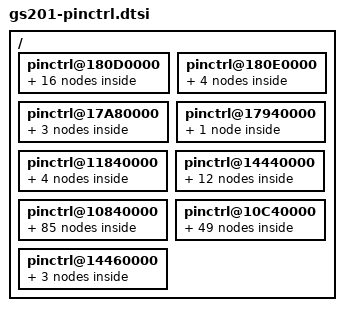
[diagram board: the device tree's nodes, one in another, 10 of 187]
// SPDX-License-Identifier: GPL-2.0-only
/*
 * Copyright 2021 Google LLC.
 *
 */

#include <dt-bindings/interrupt-controller/gs201.h>
#include <arm64/exynos/exynos-pinctrl.h>
#include "gs101-pinctrl.h"

/ {
	/* GPIO_ALIVE */
	pinctrl@180D0000 {
		gpa0: gpa0 {
			gpio-controller;
			#gpio-cells = <2>;
			interrupt-controller;
			#interrupt-cells = <3>;
			interrupt-parent = <&gic>;
			interrupts = <GIC_SPI IRQ_ALIVE_EINT0 ITLH>,
				   <GIC_SPI IRQ_ALIVE_EINT1 ITLH>,
				   <GIC_SPI IRQ_ALIVE_EINT2 ITLH>,
				   <GIC_SPI IRQ_ALIVE_EINT3 ITLH>,
				   <GIC_SPI IRQ_ALIVE_EINT4 ITLH>,
				   <GIC_SPI IRQ_ALIVE_EINT5 ITLH>,
				   <GIC_SPI IRQ_ALIVE_EINT6 ITLH>,
				   <GIC_SPI IRQ_ALIVE_EINT7 ITLH>;
		};
		gpa1: gpa1 {
			gpio-controller;
			#gpio-cells = <2>;
			interrupt-controller;
			#interrupt-cells = <3>;
			interrupt-parent = <&gic>;
			interrupts = <GIC_SPI IRQ_ALIVE_EINT8 ITLH>,
				   <GIC_SPI IRQ_ALIVE_EINT9 ITLH>,
				   <GIC_SPI IRQ_ALIVE_EINT10 ITLH>,
				   <GIC_SPI IRQ_ALIVE_EINT11 ITLH>,
				   <GIC_SPI IRQ_ALIVE_EINT12 ITLH>,
				   <GIC_SPI IRQ_ALIVE_EINT13 ITLH>,
				   <GIC_SPI IRQ_ALIVE_EINT14 ITLH>;
		};
		gpa2: gpa2 {
			gpio-controller;
			#gpio-cells = <2>;
			interrupt-controller;
			#interrupt-cells = <3>;
			interrupt-parent = <&gic>;
			interrupts = <GIC_SPI IRQ_ALIVE_EINT15 ITLH>,
				   <GIC_SPI IRQ_ALIVE_EINT16 ITLH>,
				   <GIC_SPI IRQ_ALIVE_EINT17 ITLH>,
				   <GIC_SPI IRQ_ALIVE_EINT18 ITLH>;
		};
		gpa3: gpa3 {
			gpio-controller;
			#gpio-cells = <2>;
			interrupt-controller;
			#interrupt-cells = <3>;
			interrupt-parent = <&gic>;
			interrupts = <GIC_SPI IRQ_ALIVE_EINT20 ITLH>,
				   <GIC_SPI IRQ_ALIVE_EINT21 ITLH>,
				   <GIC_SPI IRQ_ALIVE_EINT22 ITLH>,
				   <GIC_SPI IRQ_ALIVE_EINT23 ITLH>;
		};
		gpa4: gpa4 {
			gpio-controller;
			#gpio-cells = <2>;
			interrupt-controller;
			#interrupt-cells = <3>;
			interrupt-parent = <&gic>;
			interrupts = <GIC_SPI IRQ_ALIVE_EINT24 ITLH>,
				   <GIC_SPI IRQ_ALIVE_EINT25 ITLH>,
				   <GIC_SPI IRQ_ALIVE_EINT26 ITLH>,
				   <GIC_SPI IRQ_ALIVE_EINT27 ITLH>;
		};
		gpa5: gpa5 {
			gpio-controller;
			#gpio-cells = <2>;
			interrupt-controller;
			#interrupt-cells = <3>;
			interrupts = <GIC_SPI IRQ_ALIVE_EINT28 ITLH>,
				   <GIC_SPI IRQ_ALIVE_EINT29 ITLH>,
				   <GIC_SPI IRQ_ALIVE_EINT30 ITLH>,
				   <GIC_SPI IRQ_ALIVE_EINT31 ITLH>,
				   <GIC_SPI IRQ_ALIVE_EINT32 ITLH>,
				   <GIC_SPI IRQ_ALIVE_EINT33 ITLH>,
				   <GIC_SPI IRQ_ALIVE_EINT34 ITLH>;
		};
		gpa9: gpa9 {
			gpio-controller;
			#gpio-cells = <2>;
			interrupt-controller;
			#interrupt-cells = <3>;
			interrupts = <GIC_SPI IRQ_ALIVE_EINT35 ITLH>,
				   <GIC_SPI IRQ_ALIVE_EINT36 ITLH>,
				   <GIC_SPI IRQ_ALIVE_EINT37 ITLH>,
				   <GIC_SPI IRQ_ALIVE_EINT38 ITLH>,
				   <GIC_SPI IRQ_ALIVE_EINT39 ITLH>,
				   <GIC_SPI IRQ_ALIVE_EINT40 ITLH>,
				   <GIC_SPI IRQ_ALIVE_EINT41 ITLH>,
				   <GIC_SPI IRQ_ALIVE_EINT42 ITLH>;
		};
		gpa10: gpa10 {
			gpio-controller;
			#gpio-cells = <2>;
			interrupt-controller;
			#interrupt-cells = <3>;
			interrupts = <GIC_SPI IRQ_ALIVE_EINT43 ITLH>,
				   <GIC_SPI IRQ_ALIVE_EINT44 ITLH>;
		};

		uart17_bus: uart17-bus {
		       samsung,pins = "gpa2-2", "gpa2-3";
		       samsung,pin-function = <2>;
		       samsung,pin-pud = <0>;
		};

		uart18_bus: uart18-bus {
		       samsung,pins = "gpa3-0", "gpa3-1", "gpa3-2", "gpa3-3";
		       samsung,pin-function = <EXYNOS_PIN_FUNC_2>;
		       samsung,pin-pud = <EXYNOS_PIN_PULL_NONE>;
		};

		uart18_bus_rts: uart1-bus-rts {
		       samsung,pins = "gpa3-2";
		       samsung,pin-function = <EXYNOS_PIN_FUNC_OUTPUT>;
		       samsung,pin-pud = <EXYNOS_PIN_PULL_NONE>;
		       samsung,pin-val = <1>;
		};

		uart18_bus_tx_dat: uart1-bus-tx-dat {
		       samsung,pins = "gpa3-1";
		       samsung,pin-val = <1>;
		};

		uart18_bus_tx_con: uart1-bus-tx-con {
		       samsung,pins = "gpa3-1";
		       samsung,pin-function = <EXYNOS_PIN_FUNC_OUTPUT>;
		};

		uart19_bus: uart19-bus {
		       samsung,pins = "gpa4-0", "gpa4-1", "gpa4-2", "gpa4-3";
		       samsung,pin-function = <2>;
		       samsung,pin-pud = <0>;
		};

		spi17_bus: spi17-bus {
			samsung,pins = "gpa4-0", "gpa4-1", "gpa4-2";
			samsung,pin-function = <EXYNOS_PIN_FUNC_2>;
			samsung,pin-pud = <EXYNOS_PIN_PULL_NONE>;
			samsung,pin-drv = <GS101_PIN_DRV_2_5_MA>;
		};

		spi17_cs: spi17-cs {
			samsung,pins = "gpa4-3";
			samsung,pin-function = <EXYNOS_PIN_FUNC_OUTPUT>;
			samsung,pin-pud = <EXYNOS_PIN_PULL_NONE>;
			samsung,pin-drv = <GS101_PIN_DRV_2_5_MA>;
		};
	};
	/* GPIO_FAR_ALIVE */
	pinctrl@180E0000 {
		gpa6: gpa6 {
			gpio-controller;
			#gpio-cells = <2>;
			interrupt-controller;
			#interrupt-cells = <3>;
			interrupt-parent = <&gic>;
			interrupts = <GIC_SPI IRQ_ALIVE_EINT45 ITLH>,
				   <GIC_SPI IRQ_ALIVE_EINT46 ITLH>,
				   <GIC_SPI IRQ_ALIVE_EINT47 ITLH>,
				   <GIC_SPI IRQ_ALIVE_EINT48 ITLH>,
				   <GIC_SPI IRQ_ALIVE_EINT49 ITLH>,
				   <GIC_SPI IRQ_ALIVE_EINT50 ITLH>,
				   <GIC_SPI IRQ_ALIVE_EINT51 ITLH>,
				   <GIC_SPI IRQ_ALIVE_EINT52 ITLH>;
		};
		gpa7: gpa7 {
			gpio-controller;
			#gpio-cells = <2>;
			interrupt-controller;
			#interrupt-cells = <3>;
			interrupt-parent = <&gic>;
			interrupts = <GIC_SPI IRQ_ALIVE_EINT53 ITLH>,
				   <GIC_SPI IRQ_ALIVE_EINT54 ITLH>,
				   <GIC_SPI IRQ_ALIVE_EINT55 ITLH>,
				   <GIC_SPI IRQ_ALIVE_EINT56 ITLH>;
		};
		gpa8: gpa8 {
			gpio-controller;
			#gpio-cells = <2>;
			interrupt-controller;
			#interrupt-cells = <3>;
			interrupt-parent = <&gic>;
			interrupts = <GIC_SPI IRQ_ALIVE_EINT57 ITLH>,
				   <GIC_SPI IRQ_ALIVE_EINT58 ITLH>,
				   <GIC_SPI IRQ_ALIVE_EINT59 ITLH>,
				   <GIC_SPI IRQ_ALIVE_EINT60 ITLH>,
				   <GIC_SPI IRQ_ALIVE_EINT61 ITLH>,
				   <GIC_SPI IRQ_ALIVE_EINT62 ITLH>,
				   <GIC_SPI IRQ_ALIVE_EINT63 ITLH>,
				   <GIC_SPI IRQ_ALIVE_EINT64 ITLH>;
		};
		gpa11: gpa11 {
			gpio-controller;
			#gpio-cells = <2>;
			interrupt-controller;
			#interrupt-cells = <3>;
			interrupt-parent = <&gic>;
			interrupts = <GIC_SPI IRQ_ALIVE_EINT65 ITLH>,
				   <GIC_SPI IRQ_ALIVE_EINT66 ITLH>;
		};

	};
	/* GPIO_GSACORE */
	pinctrl@17A80000 {
		gps0: gps0 {
			gpio-controller;
			#gpio-cells = <2>;
			interrupt-controller;
			#interrupt-cells = <3>;
		};
		gps1: gps1 {
			gpio-controller;
			#gpio-cells = <2>;
			interrupt-controller;
			#interrupt-cells = <3>;
		};
		gps2: gps2 {
			gpio-controller;
			#gpio-cells = <2>;
			interrupt-controller;
			#interrupt-cells = <3>;
		};
	};
	/* GPIO_GSACTRL */
	pinctrl@17940000 {
		gps3: gps3 {
			gpio-controller;
			#gpio-cells = <2>;
			interrupt-controller;
			#interrupt-cells = <3>;
		};
	};
	/* GPIO_HSI1 */
	pinctrl@11840000 {
		gph0: gph0 {
			gpio-controller;
			#gpio-cells = <2>;
			interrupt-controller;
			#interrupt-cells = <3>;
		};
		gph1: gph1 {
			gpio-controller;
			#gpio-cells = <2>;
			interrupt-controller;
			#interrupt-cells = <3>;
		};
		pcie0_clkreq: pcie0_clkreq {
			samsung,pins = "gph0-1";
			samsung,pin-function = <2>;
			samsung,pin-pud = <3>;
			samsung,pin-drv = <GS101_PIN_DRV_2_5_MA>;
			samsung,pin-con-pdn = <3>;
			samsung,pin-pud-pdn = <3>;
		};
		pcie0_perst: pcie0_perst {
			samsung,pins = "gph0-0";
			samsung,pin-function = <1>;
			samsung,pin-drv = <GS101_PIN_DRV_2_5_MA>;
			samsung,pin-con-pdn = <3>;
		};
	};
	/* GPIO_HSI2 */
	pinctrl@14440000 {
		gph2: gph2 {
			gpio-controller;
			#gpio-cells = <2>;
			interrupt-controller;
			#interrupt-cells = <3>;
		};
		gph4: gph4 {
			gpio-controller;
			#gpio-cells = <2>;
			interrupt-controller;
			#interrupt-cells = <3>;
		};

		sd2_clk: sd2-clk {
			samsung,pins = "gph4-0";
			samsung,pin-function = <2>;
			samsung,pin-pud = <0>;
			samsung,pin-drv = <GS101_PIN_DRV_7_5_MA>;
		};

		sd2_cmd: sd2-cmd {
			samsung,pins = "gph4-1";
			samsung,pin-function = <2>;
			samsung,pin-pud = <3>;
			samsung,pin-drv = <GS101_PIN_DRV_7_5_MA>;
		};

		sd2_bus1: sd2-bus-width1 {
			samsung,pins = "gph4-2";
			samsung,pin-function = <2>;
			samsung,pin-pud = <3>;
			samsung,pin-drv = <GS101_PIN_DRV_7_5_MA>;
		};

		sd2_bus4: sd2-bus-width4 {
			samsung,pins = "gph4-3", "gph4-4", "gph4-5";
			samsung,pin-function = <2>;
			samsung,pin-pud = <3>;
			samsung,pin-drv = <GS101_PIN_DRV_7_5_MA>;
		};

		sd2_clk_fast_slew_rate_1x: sd2-clk_fast_slew_rate_1x {
			samsung,pins = "gph4-0";
			samsung,pin-function = <2>;
			samsung,pin-pud = <0>;
			samsung,pin-drv = <GS101_PIN_DRV_2_5_MA>;
		};

		sd2_clk_fast_slew_rate_2x: sd2-clk_fast_slew_rate_2x {
			samsung,pins = "gph4-0";
			samsung,pin-function = <2>;
			samsung,pin-pud = <0>;
			samsung,pin-drv = <GS101_PIN_DRV_5_MA>;
		};

		sd2_clk_fast_slew_rate_3x: sd2-clk_fast_slew_rate_3x {
			samsung,pins = "gph4-0";
			samsung,pin-function = <2>;
			samsung,pin-pud = <0>;
			samsung,pin-drv = <GS101_PIN_DRV_7_5_MA>;
		};

		sd2_clk_fast_slew_rate_4x: sd2-clk_fast_slew_rate_4x {
			samsung,pins = "gph4-0";
			samsung,pin-function = <2>;
			samsung,pin-pud = <0>;
			samsung,pin-drv = <GS101_PIN_DRV_10_MA>;
		};
		pcie1_clkreq: pcie1_clkreq {
			samsung,pins = "gph2-1";
			samsung,pin-function = <2>;
			samsung,pin-pud = <3>;
			samsung,pin-drv = <GS101_PIN_DRV_2_5_MA>;
			samsung,pin-con-pdn = <3>;
			samsung,pin-pud-pdn = <3>;
		};
		pcie1_perst: pcie1_perst {
			samsung,pins = "gph2-0";
			samsung,pin-function = <1>;
			samsung,pin-drv = <GS101_PIN_DRV_2_5_MA>;
			samsung,pin-pud = <EXYNOS_PIN_PULL_NONE>;
			samsung,pin-pud-pdn = <EXYNOS_PIN_PULL_NONE>;
			samsung,pin-con-pdn = <3>;
		};
	};
	/* GPIO_PERIC0 */
	pinctrl@10840000 {
		gpp0: gpp0 {
			gpio-controller;
			#gpio-cells = <2>;
			interrupt-controller;
			#interrupt-cells = <3>;
		};
		gpp1: gpp1 {
			gpio-controller;
			#gpio-cells = <2>;
			interrupt-controller;
			#interrupt-cells = <3>;
		};
		gpp2: gpp2 {
			gpio-controller;
			#gpio-cells = <2>;
			interrupt-controller;
			#interrupt-cells = <3>;
		};
		gpp3: gpp3 {
			gpio-controller;
			#gpio-cells = <2>;
			interrupt-controller;
			#interrupt-cells = <3>;
		};
		gpp4: gpp4 {
			gpio-controller;
			#gpio-cells = <2>;
			interrupt-controller;
			#interrupt-cells = <3>;
		};
		gpp5: gpp5 {
			gpio-controller;
			#gpio-cells = <2>;
			interrupt-controller;
			#interrupt-cells = <3>;
		};
		gpp6: gpp6 {
			gpio-controller;
			#gpio-cells = <2>;
			interrupt-controller;
			#interrupt-cells = <3>;
		};
		gpp7: gpp7 {
			gpio-controller;
			#gpio-cells = <2>;
			interrupt-controller;
			#interrupt-cells = <3>;
		};
		gpp8: gpp8 {
			gpio-controller;
			#gpio-cells = <2>;
			interrupt-controller;
			#interrupt-cells = <3>;
		};
		gpp9: gpp9 {
			gpio-controller;
			#gpio-cells = <2>;
			interrupt-controller;
			#interrupt-cells = <3>;
		};
		gpp10: gpp10 {
			gpio-controller;
			#gpio-cells = <2>;
			interrupt-controller;
			#interrupt-cells = <3>;
		};
		gpp11: gpp11 {
			gpio-controller;
			#gpio-cells = <2>;
			interrupt-controller;
			#interrupt-cells = <3>;
		};
		gpp12: gpp12 {
			gpio-controller;
			#gpio-cells = <2>;
			interrupt-controller;
			#interrupt-cells = <3>;
		};
		gpp13: gpp13 {
			gpio-controller;
			#gpio-cells = <2>;
			interrupt-controller;
			#interrupt-cells = <3>;
		};
		gpp14: gpp14 {
			gpio-controller;
			#gpio-cells = <2>;
			interrupt-controller;
			#interrupt-cells = <3>;
		};
		gpp15: gpp15 {
			gpio-controller;
			#gpio-cells = <2>;
			interrupt-controller;
			#interrupt-cells = <3>;
		};
		gpp16: gpp16 {
			gpio-controller;
			#gpio-cells = <2>;
			interrupt-controller;
			#interrupt-cells = <3>;
		};
		gpp17: gpp17 {
			gpio-controller;
			#gpio-cells = <2>;
			interrupt-controller;
			#interrupt-cells = <3>;
		};
		gpp18: gpp18 {
			gpio-controller;
			#gpio-cells = <2>;
			interrupt-controller;
			#interrupt-cells = <3>;
		};
		gpp19: gpp19 {
			gpio-controller;
			#gpio-cells = <2>;
			interrupt-controller;
			#interrupt-cells = <3>;
		};
		/* USI_PERIC0_UART_DBG */
		uart0_bus: uart0-bus {
			samsung,pins = "gpp1-2", "gpp1-3";
			samsung,pin-function = <2>;
			samsung,pin-pud = <0>;
		};

		disp_te_pri_on: disp-te-pri-on {
			samsung,pins = "gpp0-3";
			samsung,pin-function = <0xf>;
		};

		disp_te_pri_off: disp-te-pri-off {
			samsung,pins = "gpp0-3";
			samsung,pin-function = <0>;
		};

		disp_te_sec_on: disp-te-sec-on {
			samsung,pins = "gpp0-4";
			samsung,pin-function = <0xf>;
		};

		disp_te_sec_off: disp-te-sec-off {
			samsung,pins = "gpp0-4";
			samsung,pin-function = <0>;
		};

		sensor_mclk1_out: sensor-mclk1-out {
			samsung,pins = "gpp3-0";
			samsung,pin-function = <EXYNOS_PIN_FUNC_OUTPUT>;
			samsung,pin-pud = <EXYNOS_PIN_PULL_DOWN>;
			samsung,pin-drv = <GS101_PIN_DRV_2_5_MA>;
		};
		sensor_mclk1_fn: sensor-mclk1-fn {
			samsung,pins = "gpp3-0";
			samsung,pin-function = <EXYNOS_PIN_FUNC_2>;
			samsung,pin-pud = <EXYNOS_PIN_PULL_NONE>;
			samsung,pin-drv = <GS101_PIN_DRV_2_5_MA>;
		};
		sensor_mclk2_out: sensor-mclk2-out {
			samsung,pins = "gpp5-0";
			samsung,pin-function = <EXYNOS_PIN_FUNC_OUTPUT>;
			samsung,pin-pud = <EXYNOS_PIN_PULL_DOWN>;
			samsung,pin-drv = <GS101_PIN_DRV_2_5_MA>;
		};
		sensor_mclk2_fn: sensor-mclk2-fn {
			samsung,pins = "gpp5-0";
			samsung,pin-function = <EXYNOS_PIN_FUNC_2>;
			samsung,pin-pud = <EXYNOS_PIN_PULL_NONE>;
			samsung,pin-drv = <GS101_PIN_DRV_2_5_MA>;
		};
		sensor_mclk3_out: sensor-mclk3-out {
			samsung,pins = "gpp7-0";
			samsung,pin-function = <EXYNOS_PIN_FUNC_OUTPUT>;
			samsung,pin-pud = <EXYNOS_PIN_PULL_DOWN>;
			samsung,pin-drv = <GS101_PIN_DRV_2_5_MA>;
		};
		sensor_mclk3_fn: sensor-mclk3-fn {
			samsung,pins = "gpp7-0";
			samsung,pin-function = <EXYNOS_PIN_FUNC_2>;
			samsung,pin-pud = <EXYNOS_PIN_PULL_NONE>;
			samsung,pin-drv = <GS101_PIN_DRV_2_5_MA>;
		};
		sensor_mclk4_out: sensor-mclk4-out {
			samsung,pins = "gpp9-0";
			samsung,pin-function = <EXYNOS_PIN_FUNC_OUTPUT>;
			samsung,pin-pud = <EXYNOS_PIN_PULL_DOWN>;
			samsung,pin-drv = <GS101_PIN_DRV_2_5_MA>;
		};
		sensor_mclk4_fn: sensor-mclk4-fn {
			samsung,pins = "gpp9-0";
			samsung,pin-function = <EXYNOS_PIN_FUNC_2>;
			samsung,pin-pud = <EXYNOS_PIN_PULL_NONE>;
			samsung,pin-drv = <GS101_PIN_DRV_2_5_MA>;
		};
		sensor_mclk5_out: sensor-mclk5-out {
			samsung,pins = "gpp11-0";
			samsung,pin-function = <EXYNOS_PIN_FUNC_OUTPUT>;
			samsung,pin-pud = <EXYNOS_PIN_PULL_DOWN>;
			samsung,pin-drv = <GS101_PIN_DRV_5_MA>;
		};
		sensor_mclk5_fn: sensor-mclk5-fn {
			samsung,pins = "gpp11-0";
			samsung,pin-function = <EXYNOS_PIN_FUNC_2>;
			samsung,pin-pud = <EXYNOS_PIN_PULL_NONE>;
			samsung,pin-drv = <GS101_PIN_DRV_5_MA>;
		};
		sensor_mclk6_out: sensor-mclk6-out {
			samsung,pins = "gpp13-0";
			samsung,pin-function = <EXYNOS_PIN_FUNC_OUTPUT>;
			samsung,pin-pud = <EXYNOS_PIN_PULL_DOWN>;
			samsung,pin-drv = <GS101_PIN_DRV_5_MA>;
		};
		sensor_mclk6_fn: sensor-mclk6-fn {
			samsung,pins = "gpp13-0";
			samsung,pin-function = <EXYNOS_PIN_FUNC_2>;
			samsung,pin-pud = <EXYNOS_PIN_PULL_NONE>;
			samsung,pin-drv = <GS101_PIN_DRV_5_MA>;
		};
		sensor_mclk7_out: sensor-mclk7-out {
			samsung,pins = "gpp15-0";
			samsung,pin-function = <EXYNOS_PIN_FUNC_OUTPUT>;
			samsung,pin-pud = <EXYNOS_PIN_PULL_DOWN>;
			samsung,pin-drv = <GS101_PIN_DRV_5_MA>;
		};
		sensor_mclk7_fn: sensor-mclk7-fn {
			samsung,pins = "gpp15-0";
			samsung,pin-function = <EXYNOS_PIN_FUNC_2>;
			samsung,pin-pud = <EXYNOS_PIN_PULL_NONE>;
			samsung,pin-drv = <GS101_PIN_DRV_5_MA>;
		};
		sensor_mclk8_out: sensor-mclk8-out {
			samsung,pins = "gpp17-0";
			samsung,pin-function = <EXYNOS_PIN_FUNC_OUTPUT>;
			samsung,pin-pud = <EXYNOS_PIN_PULL_DOWN>;
			samsung,pin-drv = <GS101_PIN_DRV_5_MA>;
		};
		sensor_mclk8_fn: sensor-mclk8-fn {
			samsung,pins = "gpp17-0";
			samsung,pin-function = <EXYNOS_PIN_FUNC_2>;
			samsung,pin-pud = <EXYNOS_PIN_PULL_NONE>;
			samsung,pin-drv = <GS101_PIN_DRV_5_MA>;
		};
		hsi2c14_bus: hsi2c14-bus {
			samsung,pins = "gpp18-0", "gpp18-1";
			samsung,pin-function = <2>;
			samsung,pin-pud = <0>;
			samsung,pin-drv = <GS101_PIN_DRV_2_5_MA>;
		};
		uart14_bus_single: uart14-bus {
			samsung,pins = "gpp18-0", "gpp18-1",
			   "gpp18-2", "gpp18-3";
			samsung,pin-function = <2>;
			samsung,pin-pud = <0>;
		};
		spi14_bus: spi14-bus {
			samsung,pins = "gpp18-0", "gpp18-1", "gpp18-2";
			samsung,pin-function = <2>;
			samsung,pin-pud = <0>;
			samsung,pin-drv = <GS101_PIN_DRV_2_5_MA>;
		};
		spi14_cs: spi14-cs {
			samsung,pins = "gpp18-3";
			samsung,pin-function = <1>;
			samsung,pin-pud = <0>;
			samsung,pin-drv = <GS101_PIN_DRV_2_5_MA>;
		};
		spi14_cs_func: spi14-cs-func {
			samsung,pins = "gpp18-3";
			samsung,pin-function = <2>;
			samsung,pin-pud = <0>;
			samsung,pin-drv = <GS101_PIN_DRV_2_5_MA>;
		};
		hsi2c8_bus: hsi2c8-bus {
			samsung,pins = "gpp16-0", "gpp16-1";
			samsung,pin-function = <EXYNOS_PIN_FUNC_3>;
			samsung,pin-pud = <EXYNOS_PIN_PULL_NONE>;
			samsung,pin-drv = <GS101_PIN_DRV_2_5_MA>;
			samsung,pin-pud-pdn = <EXYNOS_PIN_PDN_OUT0>;
		};
		uart8_bus_single: uart8-bus {
			samsung,pins = "gpp16-0", "gpp16-1", "gpp16-2",
			  "gpp16-3";
			samsung,pin-function = <3>;
			samsung,pin-pud = <0>;
		};
		spi8_bus: spi8-bus {
			samsung,pins = "gpp16-0", "gpp16-1", "gpp16-2";
			samsung,pin-function = <3>;
			samsung,pin-pud = <0>;
			samsung,pin-drv = <GS101_PIN_DRV_2_5_MA>;
		};
		spi8_cs: spi8-cs {
			samsung,pins = "gpp16-3";
			samsung,pin-function = <1>;
			samsung,pin-pud = <0>;
			samsung,pin-drv = <GS101_PIN_DRV_2_5_MA>;
		};
		spi8_cs_func: spi8-cs-func {
			samsung,pins = "gpp16-3";
			samsung,pin-function = <3>;
			samsung,pin-pud = <0>;
			samsung,pin-drv = <GS101_PIN_DRV_2_5_MA>;
		};
		hsi2c7_bus: hsi2c7-bus {
			samsung,pins = "gpp14-0", "gpp14-1";
			samsung,pin-function = <3>;
			samsung,pin-pud = <0>;
			samsung,pin-drv = <GS101_PIN_DRV_2_5_MA>;
		};
		uart7_bus_single: uart7-bus {
			samsung,pins = "gpp14-0", "gpp14-1",
			      "gpp14-2", "gpp14-3";
			samsung,pin-function = <3>;
			samsung,pin-pud = <0>;
		};
		spi7_bus: spi7-bus {
			samsung,pins = "gpp14-0", "gpp14-1", "gpp14-2";
			samsung,pin-function = <3>;
			samsung,pin-pud = <0>;
			samsung,pin-drv = <GS101_PIN_DRV_2_5_MA>;
		};
		spi7_cs: spi7-cs {
			samsung,pins = "gpp14-3";
			samsung,pin-function = <1>;
			samsung,pin-pud = <0>;
			samsung,pin-drv = <GS101_PIN_DRV_2_5_MA>;
		};
		spi7_cs_func: spi7-cs-func {
			samsung,pins = "gpp14-3";
			samsung,pin-function = <3>;
			samsung,pin-pud = <0>;
			samsung,pin-drv = <GS101_PIN_DRV_2_5_MA>;
		};
		hsi2c6_bus: hsi2c6-bus {
			samsung,pins = "gpp12-0", "gpp12-1";
			samsung,pin-function = <3>;
			samsung,pin-pud = <0>;
			samsung,pin-drv = <GS101_PIN_DRV_2_5_MA>;
		};
		uart6_bus_single: uart6-bus {
			samsung,pins = "gpp12-0", "gpp12-1",
			    "gpp12-2", "gpp12-3";
			samsung,pin-function = <3>;
			samsung,pin-pud = <0>;
		};
		spi6_bus: spi6-bus {
			samsung,pins = "gpp12-0", "gpp12-1", "gpp12-2";
			samsung,pin-function = <3>;
			samsung,pin-pud = <0>;
			samsung,pin-drv = <GS101_PIN_DRV_2_5_MA>;
		};
		spi6_cs: spi6-cs {
			samsung,pins = "gpp12-3";
			samsung,pin-function = <1>;
			samsung,pin-pud = <0>;
			samsung,pin-drv = <GS101_PIN_DRV_2_5_MA>;
		};
		spi6_cs_func: spi6-cs-func {
			samsung,pins = "gpp12-3";
			samsung,pin-function = <3>;
			samsung,pin-pud = <0>;
			samsung,pin-drv = <GS101_PIN_DRV_2_5_MA>;
		};
		hsi2c5_bus: hsi2c5-bus {
			samsung,pins = "gpp10-0", "gpp10-1";
			samsung,pin-function = <3>;
			samsung,pin-pud = <0>;
			samsung,pin-drv = <GS101_PIN_DRV_2_5_MA>;
		};
		uart5_bus_single: uart5-bus {
			samsung,pins = "gpp10-0", "gpp10-1",
			    "gpp10-2", "gpp10-3";
			samsung,pin-function = <3>;
			samsung,pin-pud = <0>;
		};
		spi5_bus: spi5-bus {
			samsung,pins = "gpp10-0", "gpp10-1", "gpp10-2";
			samsung,pin-drv = <GS101_PIN_DRV_2_5_MA>;
			samsung,pin-function = <EXYNOS_PIN_FUNC_3>;
			samsung,pin-pud = <EXYNOS_PIN_PULL_NONE>;
			samsung,pin-con-pdn = <EXYNOS_PIN_PDN_PREV>;
			samsung,pin-pud-pdn = <EXYNOS_PIN_PULL_NONE>;
		};
		spi5_cs_func: spi5-cs-func {
			samsung,pins = "gpp10-3";
			samsung,pin-drv = <GS101_PIN_DRV_2_5_MA>;
			samsung,pin-function = <EXYNOS_PIN_FUNC_3>;
			samsung,pin-pud = <EXYNOS_PIN_PULL_NONE>;
			samsung,pin-con-pdn = <EXYNOS_PIN_PDN_PREV>;
			samsung,pin-pud-pdn = <EXYNOS_PIN_PULL_NONE>;
		};
		hsi2c4_bus: hsi2c4-bus {
			samsung,pins = "gpp8-0", "gpp8-1";
			samsung,pin-function = <3>;
			samsung,pin-pud = <0>;
			samsung,pin-drv = <GS101_PIN_DRV_2_5_MA>;
		};
		uart4_bus_single: uart4-bus {
			samsung,pins = "gpp8-0", "gpp8-1",
			    "gpp8-2", "gpp8-3";
			samsung,pin-function = <3>;
			samsung,pin-pud = <0>;
		};
		spi4_bus: spi4-bus {
			samsung,pins = "gpp8-0", "gpp8-1", "gpp8-2";
			samsung,pin-function = <3>;
			samsung,pin-pud = <0>;
			samsung,pin-drv = <GS101_PIN_DRV_2_5_MA>;
		};
		spi4_cs: spi4-cs {
			samsung,pins = "gpp8-3";
			samsung,pin-function = <1>;
			samsung,pin-pud = <0>;
			samsung,pin-drv = <GS101_PIN_DRV_2_5_MA>;
		};
		spi4_cs_func: spi4-cs-func {
			samsung,pins = "gpp8-3";
			samsung,pin-function = <3>;
			samsung,pin-pud = <0>;
			samsung,pin-drv = <GS101_PIN_DRV_2_5_MA>;
		};
		hsi2c3_bus: hsi2c3-bus {
			samsung,pins = "gpp6-0", "gpp6-1";
			samsung,pin-function = <3>;
			samsung,pin-pud = <0>;
			samsung,pin-drv = <GS101_PIN_DRV_2_5_MA>;
		};
		uart3_bus_single: uart3-bus {
			samsung,pins = "gpp6-0", "gpp6-1",
			    "gpp6-2", "gpp6-3";
			samsung,pin-function = <3>;
			samsung,pin-pud = <0>;
		};
		spi3_bus: spi3-bus {
			samsung,pins = "gpp6-0", "gpp6-1", "gpp6-2";
			samsung,pin-function = <3>;
			samsung,pin-pud = <0>;
			samsung,pin-drv = <GS101_PIN_DRV_2_5_MA>;
		};
		spi3_cs: spi3-cs {
			samsung,pins = "gpp6-3";
			samsung,pin-function = <1>;
			samsung,pin-pud = <0>;
			samsung,pin-drv = <GS101_PIN_DRV_2_5_MA>;
		};
		spi3_cs_func: spi3-cs-func {
			samsung,pins = "gpp6-3";
			samsung,pin-function = <3>;
			samsung,pin-pud = <0>;
			samsung,pin-drv = <GS101_PIN_DRV_2_5_MA>;
		};
		hsi2c2_bus: hsi2c2-bus {
			samsung,pins = "gpp4-0", "gpp4-1";
			samsung,pin-function = <3>;
			samsung,pin-pud = <0>;
			samsung,pin-drv = <GS101_PIN_DRV_2_5_MA>;
		};
		uart2_bus_single: uart2-bus {
			samsung,pins = "gpp4-0", "gpp4-1",
			    "gpp4-2", "gpp4-3";
			samsung,pin-function = <3>;
			samsung,pin-pud = <0>;
		};
		spi2_bus: spi2-bus {
			samsung,pins = "gpp4-0", "gpp4-1", "gpp4-2";
			samsung,pin-function = <3>;
			samsung,pin-pud = <0>;
			samsung,pin-drv = <GS101_PIN_DRV_2_5_MA>;
		};
		spi2_cs: spi2-cs {
			samsung,pins = "gpp4-3";
			samsung,pin-function = <1>;
			samsung,pin-pud = <0>;
			samsung,pin-drv = <GS101_PIN_DRV_2_5_MA>;
		};
		spi2_cs_func: spi2-cs-func {
			samsung,pins = "gpp4-3";
			samsung,pin-function = <3>;
			samsung,pin-pud = <0>;
			samsung,pin-drv = <GS101_PIN_DRV_2_5_MA>;
		};
		hsi2c1_bus: hsi2c1-bus {
			samsung,pins = "gpp2-0", "gpp2-1";
			samsung,pin-function = <3>;
			samsung,pin-pud = <0>;
			samsung,pin-drv = <GS101_PIN_DRV_2_5_MA>;
		};
		uart1_bus_single: uart1-bus {
			samsung,pins = "gpp2-0", "gpp2-1",
			    "gpp2-2", "gpp2-3";
			samsung,pin-function = <3>;
			samsung,pin-pud = <0>;
		};
		spi1_bus: spi1-bus {
			samsung,pins = "gpp2-0", "gpp2-1", "gpp2-2";
			samsung,pin-function = <3>;
			samsung,pin-pud = <0>;
			samsung,pin-drv = <GS101_PIN_DRV_2_5_MA>;
		};
		spi1_cs: spi1-cs {
			samsung,pins = "gpp2-3";
			samsung,pin-function = <1>;
			samsung,pin-pud = <0>;
			samsung,pin-drv = <GS101_PIN_DRV_2_5_MA>;
		};
		spi1_cs_func: spi1-cs-func {
			samsung,pins = "gpp2-3";
			samsung,pin-function = <3>;
			samsung,pin-pud = <0>;
			samsung,pin-drv = <GS101_PIN_DRV_2_5_MA>;
		};
	};
	/* GPIO_PERIC1 */
	pinctrl@10C40000 {
		gpp20: gpp20 {
			gpio-controller;
			#gpio-cells = <2>;
			interrupt-controller;
			#interrupt-cells = <3>;
		};
		gpp21: gpp21 {
			gpio-controller;
			#gpio-cells = <2>;
			interrupt-controller;
			#interrupt-cells = <3>;
		};
		gpp22: gpp22 {
			gpio-controller;
			#gpio-cells = <2>;
			interrupt-controller;
			#interrupt-cells = <3>;
		};
		gpp23: gpp23 {
			gpio-controller;
			#gpio-cells = <2>;
			interrupt-controller;
			#interrupt-cells = <3>;
		};
		gpp24: gpp24 {
			gpio-controller;
			#gpio-cells = <2>;
			interrupt-controller;
			#interrupt-cells = <3>;
		};
		gpp25: gpp25 {
			gpio-controller;
			#gpio-cells = <2>;
			interrupt-controller;
			#interrupt-cells = <3>;
		};
		gpp26: gpp26 {
			gpio-controller;
			#gpio-cells = <2>;
			interrupt-controller;
			#interrupt-cells = <3>;
		};
		gpp27: gpp27 {
			gpio-controller;
			#gpio-cells = <2>;
			interrupt-controller;
			#interrupt-cells = <3>;
		};
		hsi2c16_bus: hsi2c16-bus {
			samsung,pins = "gpp26-0", "gpp26-1";
			samsung,pin-function = <2>;
			samsung,pin-pud = <0>;
			samsung,pin-drv = <GS101_PIN_DRV_2_5_MA>;
		};
		uart16_bus_single: uart16-bus {
		       samsung,pins = "gpp26-0", "gpp26-1",
			   "gpp26-2", "gpp26-3";
		       samsung,pin-function = <2>;
		       samsung,pin-pud = <0>;
		};
		spi16_bus: spi16-bus {
			samsung,pins = "gpp26-0", "gpp26-1", "gpp26-2";
			samsung,pin-function = <2>;
			samsung,pin-pud = <0>;
			samsung,pin-drv = <GS101_PIN_DRV_2_5_MA>;
		};
		spi16_cs: spi16-cs {
			samsung,pins = "gpp26-3";
			samsung,pin-function = <1>;
			samsung,pin-pud = <0>;
			samsung,pin-drv = <GS101_PIN_DRV_2_5_MA>;
		};
		spi16_cs_func: spi16-cs-func {
			samsung,pins = "gpp26-3";
			samsung,pin-function = <2>;
			samsung,pin-pud = <0>;
			samsung,pin-drv = <GS101_PIN_DRV_2_5_MA>;
		};
		hsi2c15_bus: hsi2c15-bus {
			samsung,pins = "gpp24-0", "gpp24-1";
			samsung,pin-function = <2>;
			samsung,pin-pud = <0>;
			samsung,pin-drv = <GS101_PIN_DRV_2_5_MA>;
			samsung,pin-con-pdn = <EXYNOS_PIN_PDN_PREV>;
			samsung,pin-pud-pdn = <EXYNOS_PIN_PULL_NONE>;
		};
		uart15_bus_single: uart15-bus {
		       samsung,pins = "gpp24-0", "gpp24-1",
			   "gpp24-2", "gpp24-3";
		       samsung,pin-function = <2>;
		       samsung,pin-pud = <0>;
		};
		spi15_bus: spi15-bus {
			samsung,pins = "gpp24-0", "gpp24-1", "gpp24-2";
			samsung,pin-function = <2>;
			samsung,pin-pud = <0>;
			samsung,pin-drv = <GS101_PIN_DRV_2_5_MA>;
		};
		spi15_cs: spi15-cs {
			samsung,pins = "gpp24-3";
			samsung,pin-function = <1>;
			samsung,pin-pud = <0>;
			samsung,pin-drv = <GS101_PIN_DRV_2_5_MA>;
		};
		spi15_cs_func: spi15-cs-func {
			samsung,pins = "gpp24-3";
			samsung,pin-function = <2>;
			samsung,pin-pud = <0>;
			samsung,pin-drv = <GS101_PIN_DRV_2_5_MA>;
		};
		hsi2c13_bus: hsi2c13-bus {
			samsung,pins = "gpp25-0", "gpp25-1";
			samsung,pin-function = <2>;
			samsung,pin-pud = <0>;
			samsung,pin-drv = <GS101_PIN_DRV_2_5_MA>;
		};
		uart13_bus_single: uart13-bus {
		       samsung,pins = "gpp25-0", "gpp25-1",
			   "gpp25-2", "gpp25-3";
		       samsung,pin-function = <2>;
		       samsung,pin-pud = <0>;
		};
		spi13_bus: spi13-bus {
			samsung,pins = "gpp25-0", "gpp25-1", "gpp25-2";
			samsung,pin-function = <2>;
			samsung,pin-pud = <0>;
			samsung,pin-drv = <GS101_PIN_DRV_2_5_MA>;
		};
		spi13_cs: spi13-cs {
			samsung,pins = "gpp25-3";
			samsung,pin-function = <1>;
			samsung,pin-pud = <0>;
			samsung,pin-drv = <GS101_PIN_DRV_2_5_MA>;
		};
		spi13_cs_func: spi13-cs-func {
			samsung,pins = "gpp25-3";
			samsung,pin-function = <2>;
			samsung,pin-pud = <0>;
			samsung,pin-drv = <GS101_PIN_DRV_2_5_MA>;
		};
		hsi2c12_bus: hsi2c12-bus {
			samsung,pins = "gpp23-4", "gpp23-5";
			samsung,pin-function = <2>;
			samsung,pin-pud = <0>;
			samsung,pin-drv = <GS101_PIN_DRV_2_5_MA>;
		};
		uart12_bus_single: uart12-bus {
			samsung,pins = "gpp23-4", "gpp23-5",
				   "gpp23-6", "gpp23-7";
			samsung,pin-function = <2>;
			samsung,pin-pud = <0>;
		};
		spi12_bus: spi12-bus {
			samsung,pins = "gpp23-4", "gpp23-5", "gpp23-6";
			samsung,pin-function = <2>;
			samsung,pin-pud = <0>;
			samsung,pin-drv = <GS101_PIN_DRV_2_5_MA>;
		};
		spi14_cs2: spi14-cs2 {
			samsung,pins = "gpp23-6";
			samsung,pin-function = <EXYNOS_PIN_FUNC_OUTPUT>;
			samsung,pin-pud = <EXYNOS_PIN_PULL_NONE>;
			samsung,pin-drv = <GS101_PIN_DRV_2_5_MA>;
		};
		spi12_cs: spi12-cs {
			samsung,pins = "gpp23-7";
			samsung,pin-function = <1>;
			samsung,pin-pud = <0>;
			samsung,pin-drv = <GS101_PIN_DRV_2_5_MA>;
		};
		spi12_cs_func: spi12-cs-func {
			samsung,pins = "gpp23-7";
			samsung,pin-function = <2>;
			samsung,pin-pud = <0>;
			samsung,pin-drv = <GS101_PIN_DRV_2_5_MA>;
		};
		hsi2c11_bus: hsi2c11-bus {
			samsung,pins = "gpp23-0", "gpp23-1";
			samsung,pin-function = <2>;
			samsung,pin-pud = <0>;
			samsung,pin-drv = <GS101_PIN_DRV_2_5_MA>;
		};
		uart11_bus_single: uart11-bus {
			samsung,pins = "gpp23-0", "gpp23-1",
			    "gpp23-2", "gpp23-3";
			samsung,pin-function = <2>;
			samsung,pin-pud = <0>;
		};
		spi11_bus: spi11-bus {
			samsung,pins = "gpp23-0", "gpp23-1", "gpp23-2";
			samsung,pin-function = <2>;
			samsung,pin-pud = <0>;
			samsung,pin-drv = <GS101_PIN_DRV_2_5_MA>;
		};
		spi11_cs: spi11-cs {
			samsung,pins = "gpp23-3";
			samsung,pin-function = <1>;
			samsung,pin-pud = <0>;
			samsung,pin-drv = <GS101_PIN_DRV_2_5_MA>;
		};
		spi11_cs_func: spi11-cs-func {
			samsung,pins = "gpp23-3";
			samsung,pin-function = <2>;
			samsung,pin-pud = <0>;
			samsung,pin-drv = <GS101_PIN_DRV_2_5_MA>;
		};
		hsi2c10_bus: hsi2c10-bus {
			samsung,pins = "gpp21-0", "gpp21-1";
			samsung,pin-function = <2>;
			samsung,pin-pud = <0>;
			samsung,pin-drv = <GS101_PIN_DRV_2_5_MA>;
		};
		uart10_bus_single: uart10-bus {
			samsung,pins = "gpp21-0", "gpp21-1",
			    "gpp21-2", "gpp21-3";
			samsung,pin-function = <2>;
			samsung,pin-pud = <0>;
		};
		spi10_bus: spi10-bus {
			samsung,pins = "gpp21-0", "gpp21-1", "gpp21-2";
			samsung,pin-function = <2>;
			samsung,pin-pud = <0>;
			samsung,pin-drv = <GS101_PIN_DRV_2_5_MA>;
		};
		spi10_cs: spi10-cs {
			samsung,pins = "gpp21-3";
			samsung,pin-function = <1>;
			samsung,pin-pud = <0>;
			samsung,pin-drv = <GS101_PIN_DRV_2_5_MA>;
		};
		spi10_cs_func: spi10-cs-func {
			samsung,pins = "gpp21-3";
			samsung,pin-function = <2>;
			samsung,pin-pud = <0>;
			samsung,pin-drv = <GS101_PIN_DRV_2_5_MA>;
		};
		hsi2c9_bus: hsi2c9-bus {
			samsung,pins = "gpp20-4", "gpp20-5";
			samsung,pin-function = <2>;
			samsung,pin-pud = <0>;
			samsung,pin-drv = <GS101_PIN_DRV_2_5_MA>;
		};
		uart9_bus_single: uart9-bus {
			samsung,pins = "gpp20-4", "gpp20-5",
			    "gpp20-6", "gpp20-7";
			samsung,pin-function = <2>;
			samsung,pin-pud = <0>;
		};
		spi9_bus: spi9-bus {
			samsung,pins = "gpp20-4", "gpp20-5", "gpp20-6";
			samsung,pin-function = <2>;
			samsung,pin-pud = <0>;
			samsung,pin-drv = <GS101_PIN_DRV_2_5_MA>;
		};
		spi9_cs: spi9-cs {
			samsung,pins = "gpp20-7";
			samsung,pin-function = <1>;
			samsung,pin-pud = <0>;
			samsung,pin-drv = <GS101_PIN_DRV_2_5_MA>;
		};
		spi9_cs_func: spi9-cs-func {
			samsung,pins = "gpp20-7";
			samsung,pin-function = <2>;
			samsung,pin-pud = <0>;
			samsung,pin-drv = <GS101_PIN_DRV_2_5_MA>;
		};
		hsi2c0_bus: hsi2c0-bus {
			samsung,pins = "gpp20-0", "gpp20-1";
			samsung,pin-function = <3>;
			samsung,pin-pud = <0>;
			samsung,pin-drv = <GS101_PIN_DRV_2_5_MA>;
		};
		uart0_bus_single: uart0-bus {
			samsung,pins = "gpp20-0", "gpp20-1",
			    "gpp20-2", "gpp20-3";
			samsung,pin-function = <3>;
			samsung,pin-pud = <0>;
		};
		spi0_bus: spi0-bus {
			samsung,pins = "gpp20-0", "gpp20-1", "gpp20-2";
			samsung,pin-function = <3>;
			samsung,pin-pud = <0>;
			samsung,pin-drv = <GS101_PIN_DRV_2_5_MA>;
		};
		spi0_cs: spi0-cs {
			samsung,pins = "gpp20-3";
			samsung,pin-function = <1>;
			samsung,pin-pud = <0>;
			samsung,pin-drv = <GS101_PIN_DRV_2_5_MA>;
		};
		spi0_cs_func: spi0-cs-func {
			samsung,pins = "gpp20-3";
			samsung,pin-function = <3>;
			samsung,pin-pud = <0>;
			samsung,pin-drv = <GS101_PIN_DRV_2_5_MA>;
		};
	};
	/* GPIO_HSI2UFS */
	pinctrl@14460000 {
		gph3: gph3 {
			gpio-controller;
			#gpio-cells = <2>;
			interrupt-controller;
			#interrupt-cells = <3>;
		};
		ufs_rst_n: ufs-rst-n {
			samsung,pins = "gph3-1";
			samsung,pin-function = <2>;
			samsung,pin-pud = <0>;
			samsung,pin-con-pdn = <3>;
			samsung,pin-pud-pdn = <0>;
		};
		ufs_refclk_out: ufs-refclk-out {
			samsung,pins = "gph3-0";
			samsung,pin-function = <2>;
			samsung,pin-pud = <0>;
			samsung,pin-con-pdn = <3>;
			samsung,pin-pud-pdn = <0>;
		};
	};
};
